# STM32WB15_CM4 register map
File version: 1.3
CPU: CM4 r0p1, little endian, MPU, FPU, 4 interrupt priority bits
Registers are 32-bit, read-write, reset 0x0 unless marked. A register's access mark holds for its fields unless they carry their own. Offsets are from the block's base; [hi:lo] are bit positions; 'fields as' and 'values as' point back to an identical list.

## EXTI — External interrupt/event controller
Base 0x58000800
0x00 RTSR1 — rising trigger selection register
  [20:0] RT — Rising trigger event configuration bit of Configurable Event input
0x04 FTSR1 — falling trigger selection register
  [20:0] FT — Falling trigger event configuration bit of Configurable Event input
0x08 SWIER1 — software interrupt event register
  [20:0] SWI — Software interrupt on event
0x0C PR1 — EXTI pending register
  [20:0] PIF — Configurable event inputs Pending bit
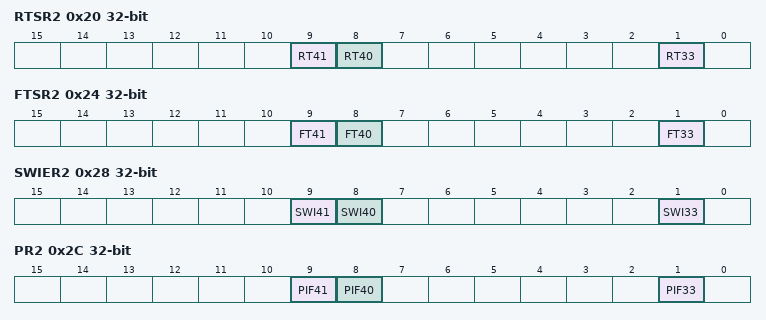
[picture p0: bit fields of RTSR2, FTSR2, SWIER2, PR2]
0x20 RTSR2 — rising trigger selection register
  [9] RT41 — Rising trigger event configuration bit of Configurable Event input 41
  [8] RT40 — Rising trigger event configuration bit of Configurable Event input 40
  [1] RT33 — Rising trigger event configuration bit of Configurable Event input
0x24 FTSR2 — falling trigger selection register
  [9] FT41 — Falling trigger event configuration bit of configurable event input 41
  [8] FT40 — Falling trigger event configuration bit of configurable event input 40
  [1] FT33 — Falling trigger event configuration bit of Configurable Event input
0x28 SWIER2 — software interrupt event register
  [9] SWI41 — Software interrupt on event
  [8] SWI40 — Software interrupt on event
  [1] SWI33 — Software interrupt on event
0x2C PR2 — pending register
  [9] PIF41 — Configurable event inputs x+32 Pending bit.
  [8] PIF40 — Configurable event inputs x+32 Pending bit.
  [1] PIF33 — Configurable event inputs x+32 Pending bit.
0x80 IMR1 reset 0x7FC00000 — CPUm wakeup with interrupt mask register
  [31:0] IM — CPU(m) wakeup with interrupt Mask on Event input
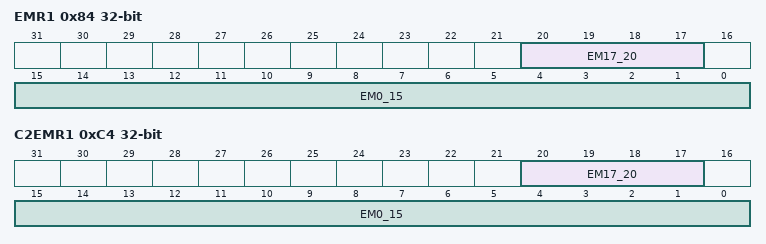
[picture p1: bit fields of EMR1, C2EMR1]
0x84 EMR1 — CPUm wakeup with event mask register
  [20:17] EM17_20 — CPU(m) Wakeup with event generation Mask on Event input
  [15:0] EM0_15 — CPU(m) Wakeup with event generation Mask on Event input
0x90 IMR2 reset 0x1FCFD — CPUm wakeup with interrupt mask register
  [17:1] IM — CPUm Wakeup with interrupt Mask on Event input
0x94 EMR2 — CPUm wakeup with event mask register
  [9:8] EM — CPU(m) Wakeup with event generation Mask on Event input
0xC0 C2IMR1 reset 0x7FC00000 — CPUm wakeup with interrupt mask register
  [31:0] IM — CPU(m) wakeup with interrupt Mask on Event input
0xC4 C2EMR1 — CPUm wakeup with event mask register
  fields as EMR1
0xD0 C2IMR2 reset 0x1FCFD — CPUm wakeup with interrupt mask register
  [17:1] IM — CPUm Wakeup with interrupt Mask on Event input
0xD4 C2EMR2 — CPUm wakeup with event mask register
  [9:8] EM — CPU(m) Wakeup with event generation Mask on Event input

## FPU — Floting point unit
Base 0xE000EF34
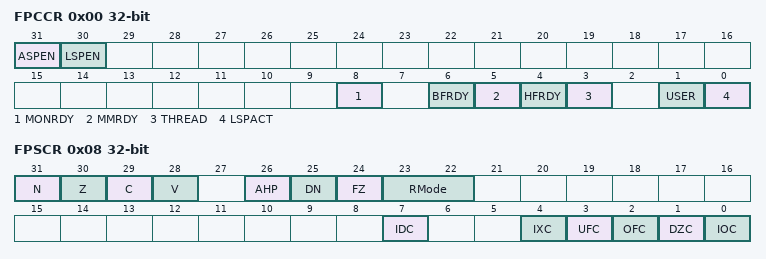
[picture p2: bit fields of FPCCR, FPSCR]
0x00 FPCCR — Floating-point context control register
  [31] ASPEN, [30] LSPEN, [8] MONRDY, [6] BFRDY, [5] MMRDY, [4] HFRDY, [3] THREAD, [1] USER, [0] LSPACT
0x04 FPCAR — Floating-point context address register
  [31:3] ADDRESS — Location of unpopulated floating-point
0x08 FPSCR — Floating-point status control register
  [31] N — Negative condition code flag
  [30] Z — Zero condition code flag
  [29] C — Carry condition code flag
  [28] V — Overflow condition code flag
  [26] AHP — Alternative half-precision control bit
  [25] DN — Default NaN mode control bit
  [24] FZ — Flush-to-zero mode control bit:
  [23:22] RMode — Rounding Mode control field
  [7] IDC — Input denormal cumulative exception bit.
  [4] IXC — Inexact cumulative exception bit
  [3] UFC — Underflow cumulative exception bit
  [2] OFC — Overflow cumulative exception bit
  [1] DZC — Division by zero cumulative exception bit.
  [0] IOC — Invalid operation cumulative exception bit

## FPU_CPACR — Floating point unit CPACR
Base 0xE000ED88
0x00 CPACR — Coprocessor access control register
  [23:20] CP

## Notices in the file
Copyright (c) 2021 STMicroelectronics.
SPDX-License-Identifier: Apache-2.0
Licensed under the Apache License, Version 2.0 (the "License");
you may not use this file except in compliance with the License.
You may obtain a copy of the License at
http://www.apache.org/licenses/LICENSE-2.0
Unless required by applicable law or agreed to in writing, software
distributed under the License is distributed on an "AS IS" BASIS,
WITHOUT WARRANTIES OR CONDITIONS OF ANY KIND, either express or implied.
See the License for the specific language governing permissions and
limitations under the License.
